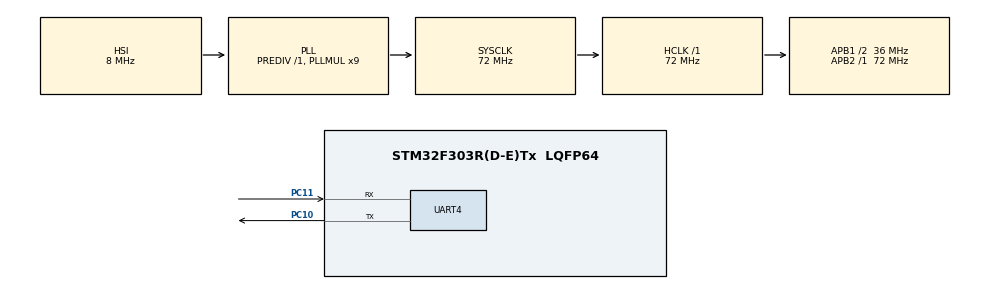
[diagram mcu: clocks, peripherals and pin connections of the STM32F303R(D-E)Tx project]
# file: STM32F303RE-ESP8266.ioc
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Mcu.Family=STM32F3
RCC.CortexFreq_Value=72000000
PC11.Signal=UART4_RX
PC10.Signal=UART4_TX
RCC.SYSCLKSourceVirtual=RCC_SYSCLKSOURCE_PLLCLK
PC10.Mode=Asynchronous
RCC.APB1CLKDivider=RCC_HCLK_DIV2
ProjectManager.StackSize=0x400
ProjectManager.TargetToolchain=STM32CubeIDE
RCC.HCLKFreq_Value=72000000
RCC.APB2TimFreq_Value=72000000
RCC.USBFreq_Value=72000000
RCC.LSE_VALUE=32768
RCC.AHBFreq_Value=72000000
RCC.HSE_VALUE=8000000
board=custom
RCC.PLLMUL=RCC_PLL_MUL9
RCC.APB2Freq_Value=72000000
Mcu.Name=STM32F303R(D-E)Tx
RCC.SYSCLKFreq_VALUE=72000000
Mcu.Package=LQFP64
ProjectManager.HeapSize=0x200
PC11.Mode=Asynchronous
RCC.HSI_VALUE=8000000
NVIC.PriorityGroup=NVIC_PRIORITYGROUP_4
RCC.APB1TimFreq_Value=72000000
RCC.APB1Freq_Value=36000000
NVIC.UART4_IRQn=true\:0\:0\:false\:false\:true\:true\:true

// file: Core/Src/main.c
/* USER CODE BEGIN Header */
/**
  ******************************************************************************
  * @file           : main.c
  * @brief          : Main program body
  ******************************************************************************
  * @attention
  *
  * <h2><center>&copy; Copyright (c) 2021 STMicroelectronics.
  * All rights reserved.</center></h2>
  *
  * This software component is licensed by ST under BSD 3-Clause license,
  * the "License"; You may not use this file except in compliance with the
  * License. You may obtain a copy of the License at:
  *                        opensource.org/licenses/BSD-3-Clause
  *
  ******************************************************************************
  */
/* USER CODE END Header */
#include "main.h"
#include "usart.h"
#include "gpio.h"

/* USER CODE BEGIN Includes */
#include "unit_test.h"
/* USER CODE END Includes */

/* USER CODE BEGIN PD */
#define RUN_UNIT_TEST
//#undef RUN_UNIT_TEST
/* USER CODE END PD */

void SystemClock_Config(void);

/* USER CODE BEGIN 0 */
int _write(int file, char *ptr, int len)
{
	int DataIdx;

	for (DataIdx = 0; DataIdx < len; DataIdx++)
	{
		ITM_SendChar(*ptr++);
	}
	return len;
}
/* USER CODE END 0 */

int main(void)
{

  /* MCU Configuration--------------------------------------------------------*/

  /* Reset of all peripherals, Initializes the Flash interface and the Systick. */
  HAL_Init();

  /* Configure the system clock */
  SystemClock_Config();

  /* Initialize all configured peripherals */
  MX_GPIO_Init();
  MX_UART4_Init();
  /* USER CODE BEGIN 2 */
  #ifdef RUN_UNIT_TEST
  	  unit_test();
  #else
  #endif
  /* USER CODE END 2 */

  /* Infinite loop */
  while (1)
  {

  }
}

void SystemClock_Config(void)
{
  RCC_OscInitTypeDef RCC_OscInitStruct = {0};
  RCC_ClkInitTypeDef RCC_ClkInitStruct = {0};
  RCC_PeriphCLKInitTypeDef PeriphClkInit = {0};

  /** Initializes the RCC Oscillators according to the specified parameters
  * in the RCC_OscInitTypeDef structure.
  */
  RCC_OscInitStruct.OscillatorType = RCC_OSCILLATORTYPE_HSI;
  RCC_OscInitStruct.HSIState = RCC_HSI_ON;
  RCC_OscInitStruct.HSICalibrationValue = RCC_HSICALIBRATION_DEFAULT;
  RCC_OscInitStruct.PLL.PLLState = RCC_PLL_ON;
  RCC_OscInitStruct.PLL.PLLSource = RCC_PLLSOURCE_HSI;
  RCC_OscInitStruct.PLL.PLLMUL = RCC_PLL_MUL9;
  RCC_OscInitStruct.PLL.PREDIV = RCC_PREDIV_DIV1;
  if (HAL_RCC_OscConfig(&RCC_OscInitStruct) != HAL_OK)
  {
    Error_Handler();
  }
  /** Initializes the CPU, AHB and APB buses clocks
  */
  RCC_ClkInitStruct.ClockType = RCC_CLOCKTYPE_HCLK|RCC_CLOCKTYPE_SYSCLK
                              |RCC_CLOCKTYPE_PCLK1|RCC_CLOCKTYPE_PCLK2;
  RCC_ClkInitStruct.SYSCLKSource = RCC_SYSCLKSOURCE_PLLCLK;
  RCC_ClkInitStruct.AHBCLKDivider = RCC_SYSCLK_DIV1;
  RCC_ClkInitStruct.APB1CLKDivider = RCC_HCLK_DIV2;
  RCC_ClkInitStruct.APB2CLKDivider = RCC_HCLK_DIV1;

  if (HAL_RCC_ClockConfig(&RCC_ClkInitStruct, FLASH_LATENCY_2) != HAL_OK)
  {
    Error_Handler();
  }
  PeriphClkInit.PeriphClockSelection = RCC_PERIPHCLK_UART4;
  PeriphClkInit.Uart4ClockSelection = RCC_UART4CLKSOURCE_PCLK1;
  if (HAL_RCCEx_PeriphCLKConfig(&PeriphClkInit) != HAL_OK)
  {
    Error_Handler();
  }
}

void Error_Handler(void)
{
  __disable_irq();
  while (1)
  {
  }
}

/************************ (C) COPYRIGHT STMicroelectronics *****END OF FILE****/
